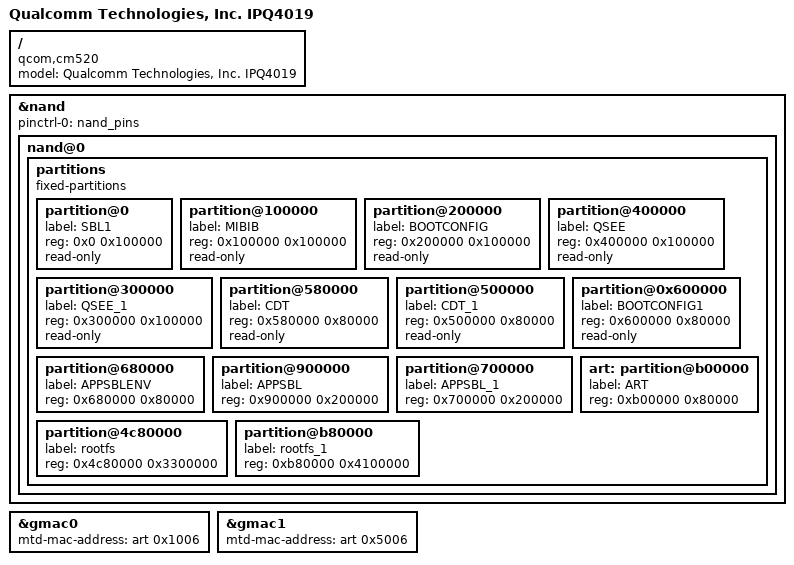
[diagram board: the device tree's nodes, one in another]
#include "qcom-ipq4019-cm520.dtsi" 

/ {
	model = "Qualcomm Technologies, Inc. IPQ4019";
	compatible = "qcom,cm520", "qcom,ipq4019";
};

&nand {
	pinctrl-0 = <&nand_pins>;
	pinctrl-names = "default";
	status = "okay";
	nand@0 {
		partitions {
			compatible = "fixed-partitions";
			#address-cells = <0x1>;
			#size-cells = <0x1>;

			partition@0 {
				label = "SBL1";
				reg = <0x0 0x100000>;
				read-only;
			};

			partition@100000 {
				label = "MIBIB";
				reg = <0x100000 0x100000>;
				read-only;
			};

			partition@200000 {
				label = "BOOTCONFIG";
				reg = <0x200000 0x100000>;
				read-only;
			};

			partition@400000 {
				label = "QSEE";
				reg = <0x400000 0x100000>;
				read-only;
			};

			partition@300000 {
				label = "QSEE_1 ";
				reg = <0x300000 0x100000>;
				read-only;
			};

			partition@580000 {
				label = "CDT";
				reg = <0x580000 0x80000>;
				read-only;
			};

			partition@500000 {
				label = "CDT_1";
				reg = <0x500000 0x80000>;
				read-only;
			};

			partition@0x600000 {
				label = "BOOTCONFIG1";
				reg = <0x600000 0x80000>;
				read-only;
			};

			partition@680000 {
				label = "APPSBLENV";
				reg = <0x680000 0x80000>;
			};

			partition@900000 {
				label = "APPSBL";
				reg = <0x900000 0x200000>;
			};

			partition@700000 {
				label = "APPSBL_1";
				reg = <0x700000 0x200000>;
			};

			art:partition@b00000 {
				label = "ART";
				reg = <0xb00000 0x80000>;
			};

			partition@4c80000 {
				label = "rootfs";
				reg = <0x4c80000 0x3300000>;
			};

			partition@b80000 {
				label = "rootfs_1";
				reg = <0xb80000 0x4100000>;
			};
		};
	};
};

&gmac0 {
	mtd-mac-address = <&art 0x1006>;
};

&gmac1 {
	mtd-mac-address = <&art 0x5006>;
};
